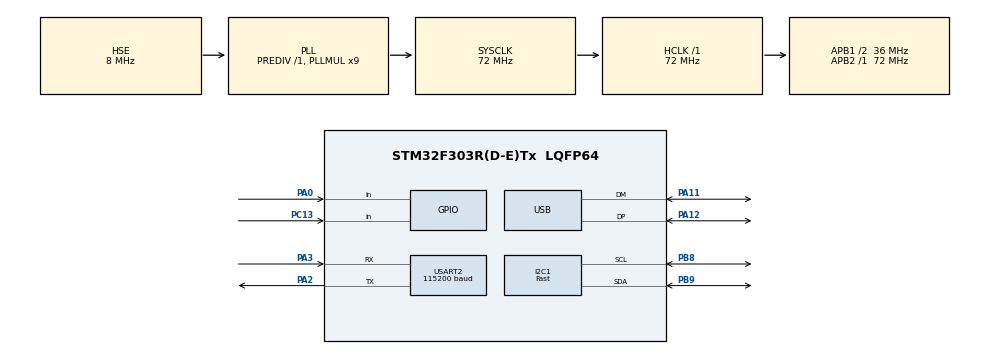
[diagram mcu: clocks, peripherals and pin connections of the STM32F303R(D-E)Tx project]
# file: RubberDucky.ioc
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I2C1.I2C_Speed_Mode=I2C_Fast
I2C1.Timing=0x0010020A
Mcu.Family=STM32F3
Mcu.Name=STM32F303R(D-E)Tx
Mcu.Package=LQFP64
NVIC.PriorityGroup=NVIC_PRIORITYGROUP_4
NVIC.USB_LP_CAN_RX0_IRQn=true\:0\:0\:false\:false\:true\:false\:true\:true
PA0.GPIO_PuPd=GPIO_PULLUP
PA0.Signal=GPIO_Input
PA11.Mode=Device
PA11.Signal=USB_DM
PA12.Mode=Device
PA12.Signal=USB_DP
PA2.Mode=Asynchronous
PA2.Signal=USART2_TX
PA3.Mode=Asynchronous
PA3.Signal=USART2_RX
PB8.Mode=I2C
PB8.Signal=I2C1_SCL
PB9.Mode=I2C
PB9.Signal=I2C1_SDA
PC13.Signal=GPIO_Input
PC14-OSC32_IN.Mode=LSE-External-Oscillator
PC14-OSC32_IN.Signal=RCC_OSC32_IN
PC15-OSC32_OUT.Mode=LSE-External-Oscillator
PC15-OSC32_OUT.Signal=RCC_OSC32_OUT
PF0-OSC_IN.Mode=HSE-External-Oscillator
PF0-OSC_IN.Signal=RCC_OSC_IN
PF1-OSC_OUT.Mode=HSE-External-Oscillator
PF1-OSC_OUT.Signal=RCC_OSC_OUT
ProjectManager.HeapSize=0x200
ProjectManager.StackSize=0x400
ProjectManager.TargetToolchain=STM32CubeIDE
RCC.AHBFreq_Value=72000000
RCC.APB1CLKDivider=RCC_HCLK_DIV2
RCC.APB1Freq_Value=36000000
RCC.APB1TimFreq_Value=72000000
RCC.APB2Freq_Value=72000000
RCC.APB2TimFreq_Value=72000000
RCC.CortexFreq_Value=72000000
RCC.HCLKFreq_Value=72000000
RCC.HSE_VALUE=8000000
RCC.HSI_VALUE=8000000
RCC.PLLMUL=RCC_PLL_MUL9
RCC.PRESCALERUSB=RCC_USBCLKSOURCE_PLL_DIV1_5
RCC.SYSCLKFreq_VALUE=72000000
RCC.SYSCLKSourceVirtual=RCC_SYSCLKSOURCE_PLLCLK
RCC.USBFreq_Value=48000000
USART2.BaudRate=115200
USART2.VirtualMode-Asynchronous=VM_ASYNC
USB_DEVICE.CLASS_NAME_FS=HID
USB_DEVICE.VirtualMode=Hid
USB_DEVICE.VirtualModeFS=Hid_FS
VP_USB_DEVICE_VS_USB_DEVICE_HID_FS.Mode=HID_FS
board=custom

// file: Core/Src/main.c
/* USER CODE BEGIN Header */
/**
  ******************************************************************************
  * @file           : main.c
  * @brief          : Main program body
  ******************************************************************************
  * @attention
  *
  * Copyright (c) 2025 STMicroelectronics.
  * All rights reserved.
  *
  * This software is licensed under terms that can be found in the LICENSE file
  * in the root directory of this software component.
  * If no LICENSE file comes with this software, it is provided AS-IS.
  *
  ******************************************************************************
  */
/* USER CODE END Header */
#include "main.h"
#include "i2c.h"
#include "usart.h"
#include "usb_device.h"
#include "gpio.h"

/* USER CODE BEGIN Includes */
#include "i2c_lcd.h"
#include "buttons.h"
#include "uart_bridge.h"

extern USBD_HandleTypeDef hUsbDeviceFS;
/* USER CODE END Includes */

/* USER CODE BEGIN PV */
// Global variable to track USB connection status
uint8_t uart_ready = 0;
/* USER CODE END PV */

void SystemClock_Config(void);

int main(void)
{

  /* MCU Configuration--------------------------------------------------------*/

  /* Reset of all peripherals, Initializes the Flash interface and the Systick. */
  HAL_Init();

  /* Configure the system clock */
  SystemClock_Config();

  /* Initialize all configured peripherals */
  MX_GPIO_Init();
  MX_USB_DEVICE_Init();
  MX_I2C1_Init();
  MX_USART2_UART_Init();
  /* USER CODE BEGIN 2 */
  // Initialize LCD
  lcd_init();
  HAL_Delay(1000);

  // Wait for USB enumeration
  HAL_Delay(2000);
  uart_ready = 1;  // Mark USB as ready

  // Display initial menu
  LCD_UpdateMenu(0);  // Show first payload option

  /* USER CODE END 2 */

  /* Infinite loop */
  while (1)
  {

    /* USER CODE BEGIN 3 */
    // Handle button inputs and menu navigation
    BUTTONS_HandleInput();

    // Small delay to prevent CPU spinning too fast
    HAL_Delay(10);
  }
  /* USER CODE END 3 */
}

void SystemClock_Config(void)
{
  RCC_OscInitTypeDef RCC_OscInitStruct = {0};
  RCC_ClkInitTypeDef RCC_ClkInitStruct = {0};
  RCC_PeriphCLKInitTypeDef PeriphClkInit = {0};

  /** Initializes the RCC Oscillators according to the specified parameters
  * in the RCC_OscInitTypeDef structure.
  */
  RCC_OscInitStruct.OscillatorType = RCC_OSCILLATORTYPE_HSI|RCC_OSCILLATORTYPE_HSE;
  RCC_OscInitStruct.HSEState = RCC_HSE_ON;
  RCC_OscInitStruct.HSIState = RCC_HSI_ON;
  RCC_OscInitStruct.HSICalibrationValue = RCC_HSICALIBRATION_DEFAULT;
  RCC_OscInitStruct.PLL.PLLState = RCC_PLL_ON;
  RCC_OscInitStruct.PLL.PLLSource = RCC_PLLSOURCE_HSE;
  RCC_OscInitStruct.PLL.PLLMUL = RCC_PLL_MUL9;
  RCC_OscInitStruct.PLL.PREDIV = RCC_PREDIV_DIV1;
  if (HAL_RCC_OscConfig(&RCC_OscInitStruct) != HAL_OK)
  {
    Error_Handler();
  }

  /** Initializes the CPU, AHB and APB buses clocks
  */
  RCC_ClkInitStruct.ClockType = RCC_CLOCKTYPE_HCLK|RCC_CLOCKTYPE_SYSCLK
                              |RCC_CLOCKTYPE_PCLK1|RCC_CLOCKTYPE_PCLK2;
  RCC_ClkInitStruct.SYSCLKSource = RCC_SYSCLKSOURCE_PLLCLK;
  RCC_ClkInitStruct.AHBCLKDivider = RCC_SYSCLK_DIV1;
  RCC_ClkInitStruct.APB1CLKDivider = RCC_HCLK_DIV2;
  RCC_ClkInitStruct.APB2CLKDivider = RCC_HCLK_DIV1;

  if (HAL_RCC_ClockConfig(&RCC_ClkInitStruct, FLASH_LATENCY_2) != HAL_OK)
  {
    Error_Handler();
  }
  PeriphClkInit.PeriphClockSelection = RCC_PERIPHCLK_USB|RCC_PERIPHCLK_USART2
                              |RCC_PERIPHCLK_I2C1;
  PeriphClkInit.Usart2ClockSelection = RCC_USART2CLKSOURCE_PCLK1;
  PeriphClkInit.I2c1ClockSelection = RCC_I2C1CLKSOURCE_HSI;
  PeriphClkInit.USBClockSelection = RCC_USBCLKSOURCE_PLL_DIV1_5;
  if (HAL_RCCEx_PeriphCLKConfig(&PeriphClkInit) != HAL_OK)
  {
    Error_Handler();
  }
}

void Error_Handler(void)
{
  __disable_irq();
  while (1)
  {
  }
}
